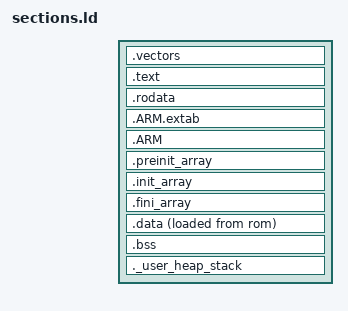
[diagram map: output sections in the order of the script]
SECTIONS
{
  .vectors :
  {
    . = ALIGN(4);
    KEEP(*(.vectors)) /* Startup code */
    . = ALIGN(4);
  } >rom

  /* The program code and other data goes into FLASH */
  .text :
  {
    . = ALIGN(4);
    *(.text)           /* .text sections (code) */
    *(.text*)          /* .text* sections (code) */
    *(.glue_7)         /* glue arm to thumb code */
    *(.glue_7t)        /* glue thumb to arm code */
    *(.eh_frame)

    KEEP (*(.init))
    KEEP (*(.fini))

    . = ALIGN(4);
    _etext = .;        /* define a global symbols at end of code */
  } >rom

  /* Constant data goes into FLASH */
  .rodata :
  {
    . = ALIGN(4);
    *(.rodata)         /* .rodata sections (constants, strings, etc.) */
    *(.rodata*)        /* .rodata* sections (constants, strings, etc.) */
    . = ALIGN(4);
  } >rom

  .ARM.extab (READONLY) : /* The "READONLY" keyword is only supported in GCC11 and later, remove it if using GCC10 or earlier. */
  {
    . = ALIGN(4);
    *(.ARM.extab* .gnu.linkonce.armextab.*)
    . = ALIGN(4);
  } >rom

  .ARM (READONLY) : /* The "READONLY" keyword is only supported in GCC11 and later, remove it if using GCC10 or earlier. */
  {
    . = ALIGN(4);
    __exidx_start = .;
    *(.ARM.exidx*)
    __exidx_end = .;
    . = ALIGN(4);
  } >rom

  .preinit_array (READONLY) : /* The "READONLY" keyword is only supported in GCC11 and later, remove it if using GCC10 or earlier. */
  {
    . = ALIGN(4);
    PROVIDE_HIDDEN (__preinit_array_start = .);
    KEEP (*(.preinit_array*))
    PROVIDE_HIDDEN (__preinit_array_end = .);
    . = ALIGN(4);
  } >rom

  .init_array (READONLY) : /* The "READONLY" keyword is only supported in GCC11 and later, remove it if using GCC10 or earlier. */
  {
    . = ALIGN(4);
    PROVIDE_HIDDEN (__init_array_start = .);
    KEEP (*(SORT(.init_array.*)))
    KEEP (*(.init_array*))
    PROVIDE_HIDDEN (__init_array_end = .);
    . = ALIGN(4);
  } >rom

  .fini_array (READONLY) : /* The "READONLY" keyword is only supported in GCC11 and later, remove it if using GCC10 or earlier. */
  {
    . = ALIGN(4);
    PROVIDE_HIDDEN (__fini_array_start = .);
    KEEP (*(SORT(.fini_array.*)))
    KEEP (*(.fini_array*))
    PROVIDE_HIDDEN (__fini_array_end = .);
    . = ALIGN(4);
  } >rom

  /* used by the startup to initialize data */
  _sidata = LOADADDR(.data);

  /* Initialized data sections goes into ram, load LMA copy after code */
  .data :
  {
    . = ALIGN(4);
    _sdata = .;        /* create a global symbol at data start */
    *(.data)           /* .data sections */
    *(.data*)          /* .data* sections */
    *(.RamFunc)        /* .RamFunc sections */
    *(.RamFunc*)       /* .RamFunc* sections */

    . = ALIGN(4);
    _edata = .;        /* define a global symbol at data end */
  } >ram AT> rom


  /* Uninitialized data section */
  . = ALIGN(4);
  .bss :
  {
    /* This is used by the startup in order to initialize the .bss secion */
    _sbss = .;         /* define a global symbol at bss start */
    __bss_start__ = _sbss;
    *(.bss)
    *(.bss*)
    *(COMMON)

    . = ALIGN(4);
    _ebss = .;         /* define a global symbol at bss end */
    __bss_end__ = _ebss;
  } >ram

  /* User_heap_stack section, used to check that there is enough ram left */
  ._user_heap_stack :
  {
    . = ALIGN(8);
    PROVIDE ( end = . );
    PROVIDE ( _end = . );
    . = . + _min_heap_size;
    . = . + _min_stack_size;
    . = ALIGN(8);
  } >ram



  /* Remove information from the standard libraries */
  /DISCARD/ :
  {
    libc.a ( * )
    libm.a ( * )
    libgcc.a ( * )
  }

}
